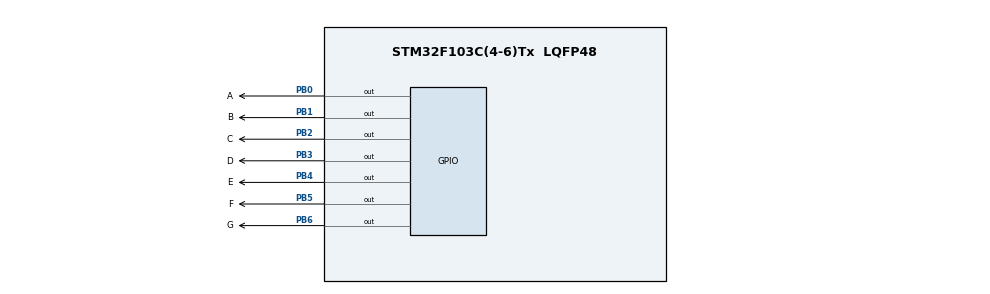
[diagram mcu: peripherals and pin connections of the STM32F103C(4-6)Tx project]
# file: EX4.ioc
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Mcu.Family=STM32F1
Mcu.Name=STM32F103C(4-6)Tx
Mcu.Package=LQFP48
NVIC.PriorityGroup=NVIC_PRIORITYGROUP_4
PB0.GPIO_Label=A
PB0.Signal=GPIO_Output
PB1.GPIO_Label=B
PB1.Signal=GPIO_Output
PB2.GPIO_Label=C
PB2.Signal=GPIO_Output
PB3.GPIO_Label=D
PB3.Signal=GPIO_Output
PB4.GPIO_Label=E
PB4.Signal=GPIO_Output
PB5.GPIO_Label=F
PB5.Signal=GPIO_Output
PB6.GPIO_Label=G
PB6.Signal=GPIO_Output
ProjectManager.HeapSize=0x200
ProjectManager.StackSize=0x400
ProjectManager.TargetToolchain=STM32CubeIDE
RCC.APB1Freq_Value=8000000
RCC.APB2Freq_Value=8000000
VP_SYS_VS_ND.Mode=No_Debug
board=custom

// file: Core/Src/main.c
/* USER CODE BEGIN Header */
/**
  ******************************************************************************
  * @file           : main.c
  * @brief          : Main program body
  ******************************************************************************
  * @attention
  *
  * <h2><center>&copy; Copyright (c) 2024 STMicroelectronics.
  * All rights reserved.</center></h2>
  *
  * This software component is licensed by ST under BSD 3-Clause license,
  * the "License"; You may not use this file except in compliance with the
  * License. You may obtain a copy of the License at:
  *                        opensource.org/licenses/BSD-3-Clause
  *
  ******************************************************************************
  */
/* USER CODE END Header */
#include "main.h"

void SystemClock_Config(void);
static void MX_GPIO_Init(void);

typedef enum{
	ZERO,ONE,TWO,THREE,FOUR,FIVE,SIX,SEVEN,EIGHT,NINCE
} number;
number setNumber=ZERO;
void display7LED(int counter){
	switch(setNumber){
	case ZERO:
		  HAL_GPIO_WritePin(A_GPIO_Port, A_Pin, RESET);
		  HAL_GPIO_WritePin(B_GPIO_Port, B_Pin, RESET);
		  HAL_GPIO_WritePin(C_GPIO_Port, C_Pin, RESET);
		  HAL_GPIO_WritePin(D_GPIO_Port, D_Pin, RESET);
		  HAL_GPIO_WritePin(E_GPIO_Port, E_Pin, RESET);
		  HAL_GPIO_WritePin(F_GPIO_Port, F_Pin, RESET);
		  HAL_GPIO_WritePin(G_GPIO_Port, G_Pin, SET);
		  setNumber=ONE;
		  break;
	case ONE:
		  HAL_GPIO_WritePin(A_GPIO_Port, A_Pin, SET);
		  HAL_GPIO_WritePin(B_GPIO_Port, B_Pin, RESET);
		  HAL_GPIO_WritePin(C_GPIO_Port, C_Pin, RESET);
		  HAL_GPIO_WritePin(D_GPIO_Port, D_Pin, SET);
		  HAL_GPIO_WritePin(E_GPIO_Port, E_Pin, SET);
		  HAL_GPIO_WritePin(F_GPIO_Port, F_Pin, SET);
		  HAL_GPIO_WritePin(G_GPIO_Port, G_Pin, SET);
		  setNumber=TWO;
		  break;
	case TWO:
		  HAL_GPIO_WritePin(A_GPIO_Port, A_Pin, RESET);
		  HAL_GPIO_WritePin(B_GPIO_Port, B_Pin, RESET);
		  HAL_GPIO_WritePin(C_GPIO_Port, C_Pin, SET);
		  HAL_GPIO_WritePin(D_GPIO_Port, D_Pin, RESET);
		  HAL_GPIO_WritePin(E_GPIO_Port, E_Pin, RESET);
		  HAL_GPIO_WritePin(F_GPIO_Port, F_Pin, SET);
		  HAL_GPIO_WritePin(G_GPIO_Port, G_Pin, RESET);
		  setNumber=THREE;
		  break;
	case THREE:
		  HAL_GPIO_WritePin(A_GPIO_Port, A_Pin, RESET);
		  HAL_GPIO_WritePin(B_GPIO_Port, B_Pin, RESET);
		  HAL_GPIO_WritePin(C_GPIO_Port, C_Pin, RESET);
		  HAL_GPIO_WritePin(D_GPIO_Port, D_Pin, RESET);
		  HAL_GPIO_WritePin(E_GPIO_Port, E_Pin, SET);
		  HAL_GPIO_WritePin(F_GPIO_Port, F_Pin, SET);
		  HAL_GPIO_WritePin(G_GPIO_Port, G_Pin, RESET);
		  setNumber=FOUR;
		  break;
	case FOUR:
		  HAL_GPIO_WritePin(A_GPIO_Port, A_Pin, SET);
		  HAL_GPIO_WritePin(B_GPIO_Port, B_Pin, RESET);
		  HAL_GPIO_WritePin(C_GPIO_Port, C_Pin, RESET);
		  HAL_GPIO_WritePin(D_GPIO_Port, D_Pin, SET);
		  HAL_GPIO_WritePin(E_GPIO_Port, E_Pin, SET);
		  HAL_GPIO_WritePin(F_GPIO_Port, F_Pin, RESET);
		  HAL_GPIO_WritePin(G_GPIO_Port, G_Pin, RESET);
		  setNumber=FIVE;
		  break;
	case FIVE:
		  HAL_GPIO_WritePin(A_GPIO_Port, A_Pin, RESET);
		  HAL_GPIO_WritePin(B_GPIO_Port, B_Pin, SET);
		  HAL_GPIO_WritePin(C_GPIO_Port, C_Pin, RESET);
		  HAL_GPIO_WritePin(D_GPIO_Port, D_Pin, RESET);
		  HAL_GPIO_WritePin(E_GPIO_Port, E_Pin, SET);
		  HAL_GPIO_WritePin(F_GPIO_Port, F_Pin, RESET);
		  HAL_GPIO_WritePin(G_GPIO_Port, G_Pin, RESET);
		  setNumber=SIX;
		  break;
	case SIX:
		  HAL_GPIO_WritePin(A_GPIO_Port, A_Pin, RESET);
		  HAL_GPIO_WritePin(B_GPIO_Port, B_Pin, SET);
		  HAL_GPIO_WritePin(C_GPIO_Port, C_Pin, RESET);
		  HAL_GPIO_WritePin(D_GPIO_Port, D_Pin, RESET);
		  HAL_GPIO_WritePin(E_GPIO_Port, E_Pin, RESET);
		  HAL_GPIO_WritePin(F_GPIO_Port, F_Pin, RESET);
		  HAL_GPIO_WritePin(G_GPIO_Port, G_Pin, RESET);
		  setNumber=SEVEN;
		  break;
	case SEVEN:
		  HAL_GPIO_WritePin(A_GPIO_Port, A_Pin, RESET);
		  HAL_GPIO_WritePin(B_GPIO_Port, B_Pin, RESET);
		  HAL_GPIO_WritePin(C_GPIO_Port, C_Pin, RESET);
		  HAL_GPIO_WritePin(D_GPIO_Port, D_Pin, SET);
		  HAL_GPIO_WritePin(E_GPIO_Port, E_Pin, SET);
		  HAL_GPIO_WritePin(F_GPIO_Port, F_Pin, SET);
		  HAL_GPIO_WritePin(G_GPIO_Port, G_Pin, SET);
		  setNumber=EIGHT;
		  break;
	case EIGHT:
		  HAL_GPIO_WritePin(A_GPIO_Port, A_Pin, RESET);
		  HAL_GPIO_WritePin(B_GPIO_Port, B_Pin, RESET);
		  HAL_GPIO_WritePin(C_GPIO_Port, C_Pin, RESET);
		  HAL_GPIO_WritePin(D_GPIO_Port, D_Pin, RESET);
		  HAL_GPIO_WritePin(E_GPIO_Port, E_Pin, RESET);
		  HAL_GPIO_WritePin(F_GPIO_Port, F_Pin, RESET);
		  HAL_GPIO_WritePin(G_GPIO_Port, G_Pin, RESET);
		  setNumber=NINCE;
		  break;
	default:
		  HAL_GPIO_WritePin(A_GPIO_Port, A_Pin, RESET);
		  HAL_GPIO_WritePin(B_GPIO_Port, B_Pin, RESET);
		  HAL_GPIO_WritePin(C_GPIO_Port, C_Pin, RESET);
		  HAL_GPIO_WritePin(D_GPIO_Port, D_Pin, RESET);
		  HAL_GPIO_WritePin(E_GPIO_Port, E_Pin, SET);
		  HAL_GPIO_WritePin(F_GPIO_Port, F_Pin, RESET);
		  HAL_GPIO_WritePin(G_GPIO_Port, G_Pin, RESET);
		  setNumber=ZERO;
		  break;
	}
}

int main(void)
{

  /* MCU Configuration--------------------------------------------------------*/

  /* Reset of all peripherals, Initializes the Flash interface and the Systick. */
  HAL_Init();

  /* Configure the system clock */
  SystemClock_Config();

  /* Initialize all configured peripherals */
  MX_GPIO_Init();

  /* Infinite loop */
  /* USER CODE BEGIN WHILE */
  int counter=0;
  while (1)
  {
    /* USER CODE END WHILE */

    /* USER CODE BEGIN 3 */
	  if(counter>=10) counter=0;
	 	  display7LED(counter++);
	 	  HAL_Delay(1000);
  	  	}
  /* USER CODE END 3 */
}

void SystemClock_Config(void)
{
  RCC_OscInitTypeDef RCC_OscInitStruct = {0};
  RCC_ClkInitTypeDef RCC_ClkInitStruct = {0};

  /** Initializes the RCC Oscillators according to the specified parameters
  * in the RCC_OscInitTypeDef structure.
  */
  RCC_OscInitStruct.OscillatorType = RCC_OSCILLATORTYPE_HSI;
  RCC_OscInitStruct.HSIState = RCC_HSI_ON;
  RCC_OscInitStruct.HSICalibrationValue = RCC_HSICALIBRATION_DEFAULT;
  RCC_OscInitStruct.PLL.PLLState = RCC_PLL_NONE;
  if (HAL_RCC_OscConfig(&RCC_OscInitStruct) != HAL_OK)
  {
    Error_Handler();
  }
  /** Initializes the CPU, AHB and APB buses clocks
  */
  RCC_ClkInitStruct.ClockType = RCC_CLOCKTYPE_HCLK|RCC_CLOCKTYPE_SYSCLK
                              |RCC_CLOCKTYPE_PCLK1|RCC_CLOCKTYPE_PCLK2;
  RCC_ClkInitStruct.SYSCLKSource = RCC_SYSCLKSOURCE_HSI;
  RCC_ClkInitStruct.AHBCLKDivider = RCC_SYSCLK_DIV1;
  RCC_ClkInitStruct.APB1CLKDivider = RCC_HCLK_DIV1;
  RCC_ClkInitStruct.APB2CLKDivider = RCC_HCLK_DIV1;

  if (HAL_RCC_ClockConfig(&RCC_ClkInitStruct, FLASH_LATENCY_0) != HAL_OK)
  {
    Error_Handler();
  }
}

static void MX_GPIO_Init(void)
{
  GPIO_InitTypeDef GPIO_InitStruct = {0};

  /* GPIO Ports Clock Enable */
  __HAL_RCC_GPIOB_CLK_ENABLE();

  /*Configure GPIO pin Output Level */
  HAL_GPIO_WritePin(GPIOB, A_Pin|B_Pin|C_Pin|D_Pin
                          |E_Pin|F_Pin|G_Pin, GPIO_PIN_RESET);

  /*Configure GPIO pins : A_Pin B_Pin C_Pin D_Pin
                           E_Pin F_Pin G_Pin */
  GPIO_InitStruct.Pin = A_Pin|B_Pin|C_Pin|D_Pin
                          |E_Pin|F_Pin|G_Pin;
  GPIO_InitStruct.Mode = GPIO_MODE_OUTPUT_PP;
  GPIO_InitStruct.Pull = GPIO_NOPULL;
  GPIO_InitStruct.Speed = GPIO_SPEED_FREQ_LOW;
  HAL_GPIO_Init(GPIOB, &GPIO_InitStruct);

}

void Error_Handler(void)
{
  __disable_irq();
  while (1)
  {
  }
}

/************************ (C) COPYRIGHT STMicroelectronics *****END OF FILE****/
